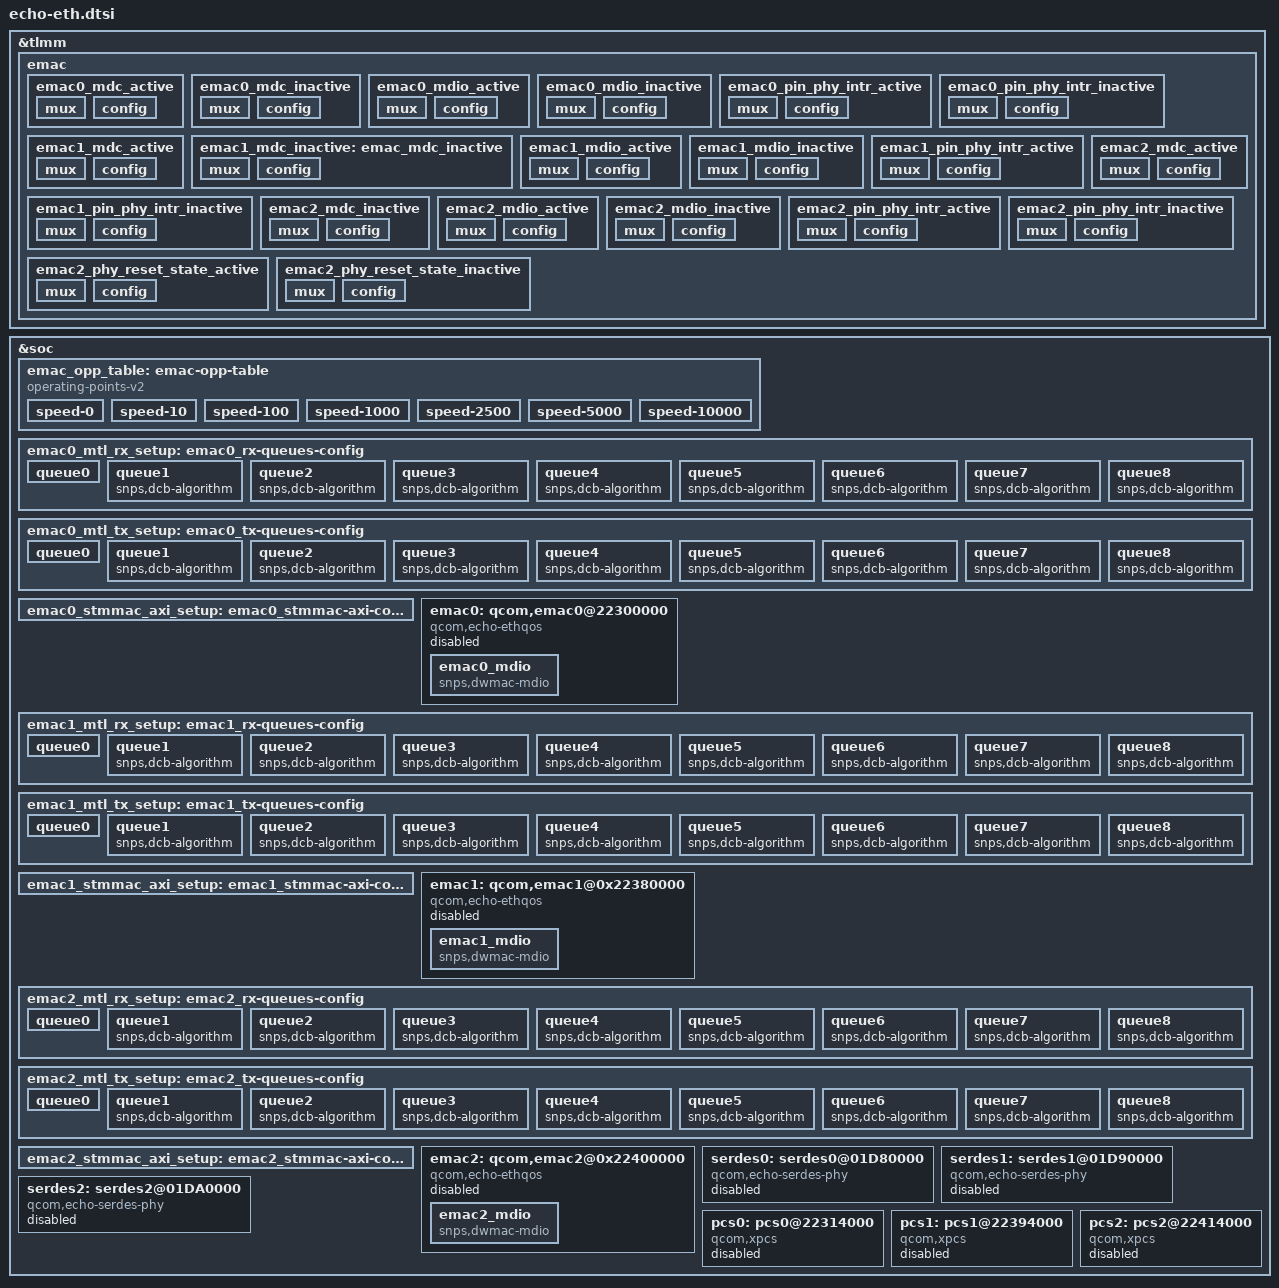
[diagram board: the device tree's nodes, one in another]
// SPDX-License-Identifier: BSD-3-Clause
/*
 * Copyright (c) Qualcomm Technologies, Inc. and/or its subsidiaries.
 */

#include <dt-bindings/clock/qcom,rpmh.h>
#include <dt-bindings/clock/qcom,echo-gcc.h>
#include <dt-bindings/clock/qcom,echo-tcsrcc.h>
#include <dt-bindings/interconnect/qcom,icc.h>
#include <dt-bindings/interconnect/qcom,echo.h>
#include <dt-bindings/interrupt-controller/arm-gic.h>
#include <dt-bindings/power/qcom,rpmhpd.h>
#include <dt-bindings/power/qcom-rpmpd.h>
#include <dt-bindings/soc/qcom,rpmh-rsc.h>
#include <dt-bindings/gpio/gpio.h>

&tlmm {
	emac {
		emac0_mdc_active: emac0_mdc_active {
			mux {
				pins = "gpio94";
				function = "eth0_mdc";
			};

			config {
				pins = "gpio94";
				bias-pull-up;
				drive-strength = <16>;
			};
		};

		emac0_mdc_inactive: emac0_mdc_inactive {
			mux {
				pins = "gpio94";
				function = "eth0_mdc";
			};

			config {
				pins = "gpio94";
				bias-pull-down;
				drive-strength = <2>;
			};
		};

		emac0_mdio_active: emac0_mdio_active {
			mux {
				pins = "gpio95";
				function = "eth0_mdio";
			};

			config {
				pins = "gpio95";
				bias-pull-up;
				drive-strength = <16>;
			};
		};

		emac0_mdio_inactive: emac0_mdio_inactive {
			mux {
				pins = "gpio95";
				function = "eth0_mdio";
			};

			config {
				pins = "gpio95";
				bias-pull-down;
				drive-strength = <2>;
			};
		};

		emac0_pin_phy_intr_active: emac0_pin_phy_intr_active {
			mux {
				pins = "gpio97";
				function = "sgmii_phy_intr0_n";
		};

			config {
				pins = "gpio97";
				drive-strength = <8>; /* 8 mA */
				bias-pull-up; /* NO PULL*/
			};
		};

		emac0_pin_phy_intr_inactive: emac0_pin_phy_intr_inactive {
			mux {
				pins = "gpio97";
				function = "sgmii_phy_intr0_n";
		};

			config {
				pins = "gpio97";
				drive-strength = <2>; /* 8 mA */
				bias-pull-down; /* NO PULL*/
			};
		};

		emac1_mdc_active: emac1_mdc_active {
			mux {
				pins = "gpio106";
				function = "eth1_mdc";
			};

			config {
				pins = "gpio106";
				bias-pull-up;
				drive-strength = <16>;
			};
		};

		emac1_mdc_inactive: emac_mdc_inactive {
			mux {
				pins = "gpio106";
				function = "eth1_mdc";
			};

			config {
				pins = "gpio106";
				bias-pull-down;
				drive-strength = <2>;
			};
		};

		emac1_mdio_active: emac1_mdio_active {
			mux {
				pins = "gpio107";
				function = "eth1_mdio";
			};

			config {
				pins = "gpio107";
				bias-pull-up;
				drive-strength = <16>;
			};
		};

		emac1_mdio_inactive: emac1_mdio_inactive {
			mux {
				pins = "gpio107";
				function = "eth1_mdio";
			};

			config {
				pins = "gpio107";
				bias-pull-down;
				drive-strength = <2>;
			};
		};

		emac1_pin_phy_intr_active: emac1_pin_phy_intr_active {
			mux {
				pins = "gpio109";
				function = "sgmii_phy_intr1_n";
		};

			config {
				pins = "gpio109";
				drive-strength = <8>; /* 8 mA */
				bias-pull-up; /* NO PULL*/
			};
		};

		emac1_pin_phy_intr_inactive: emac1_pin_phy_intr_inactive {
			mux {
				pins = "gpio109";
				function = "sgmii_phy_intr1_n";
		};

			config {
				pins = "gpio109";
				drive-strength = <2>; /* 8 mA */
				bias-pull-down; /* NO PULL*/
			};
		};

		emac2_mdc_active: emac2_mdc_active {
			mux {
				pins = "gpio86";
				function = "eth2_mdc";
			};

			config {
				pins = "gpio86";
				bias-pull-up;
				drive-strength = <16>;
			};
		};

		emac2_mdc_inactive: emac2_mdc_inactive {
			mux {
				pins = "gpio86";
				function = "eth2_mdc";
			};

			config {
				pins = "gpio86";
				bias-pull-down;
				drive-strength = <2>;
			};
		};

		emac2_mdio_active: emac2_mdio_active {
			mux {
				pins = "gpio87";
				function = "eth2_mdio";
			};

			config {
				pins = "gpio87";
				bias-pull-up;
				drive-strength = <16>;
			};
		};

		emac2_mdio_inactive: emac2_mdio_inactive {
			mux {
				pins = "gpio87";
				function = "eth2_mdio";
			};

			config {
				pins = "gpio87";
				bias-pull-down;
				drive-strength = <2>;
			};
		};

		emac2_pin_phy_intr_active: emac2_pin_phy_intr_active {
			mux {
				pins = "gpio89";
				function = "sgmii_phy_intr2_n";
		};

			config {
				pins = "gpio89";
				drive-strength = <8>; /* 8 mA */
				bias-pull-up; /* NO PULL*/
			};
		};

		emac2_pin_phy_intr_inactive: emac2_pin_phy_intr_inactive {
			mux {
				pins = "gpio89";
				function = "sgmii_phy_intr2_n";
		};

			config {
				pins = "gpio89";
				drive-strength = <2>; /* 8 mA */
				bias-pull-down; /* NO PULL*/
			};
		};

		emac2_phy_reset_state_active: emac2_phy_reset_state_active {
			mux {
				pins = "gpio88";
				function = "gpio";
			};

			config {
				pins = "gpio88";
				bias-pull-up;
				drive-strength = <16>;
			};
		};

		emac2_phy_reset_state_inactive: emac2_phy_reset_state_inactive {
			mux {
				pins = "gpio88";
				function = "gpio";
			};

			config {
				pins = "gpio88";
				bias-pull-down;
				drive-strength = <2>;
				input-enable;
			};
		};
	};
};

&soc {
	emac_opp_table: emac-opp-table {
		compatible = "operating-points-v2";

		speed-0 {
			opp-level = <0>;
			opp-avg-kBps = <0 0>;
			opp-peak-kBps = <0 0>;
		};

		speed-10 {
			opp-level = <10>;
			opp-avg-kBps = <2500 0>;
			opp-peak-kBps = <2500 2500>;
		};

		speed-100 {
			opp-level = <100>;
			opp-avg-kBps = <25000 0>;
			opp-peak-kBps = <25000 25000>;
		};

		speed-1000 {
			opp-level = <1000>;
			opp-avg-kBps = <250000 0>;
			opp-peak-kBps = <250000 250000>;
		};

		speed-2500 {
			opp-level = <2500>;
			opp-avg-kBps = <625000 0>;
			opp-peak-kBps = <625000 625000>;
		};

		speed-5000 {
			opp-level = <5000>;
			opp-avg-kBps = <1250000 0>;
			opp-peak-kBps = <1250000 1250000>;
		};

		speed-10000 {
			opp-level = <10000>;
			opp-avg-kBps = <2500000 0>;
			opp-peak-kBps = <2500000 2500000>;
		};
	};

	emac0_mtl_rx_setup: emac0_rx-queues-config {
		snps,rx-queues-to-use = <9>;
		snps,rss-queues-to-use = <1>;
		snps,rx-sched-sp;
		snps,mka_mcbcq_filtering;

		queue0 {
			snps,dcb-algorithm;
			snps,queue_depth = <16384>;
		};

		queue1 {
			snps,dcb-algorithm;
		};

		queue2 {
			snps,dcb-algorithm;
		};

		queue3 {
			snps,dcb-algorithm;
		};

		queue4 {
			snps,dcb-algorithm;
		};

		queue5 {
			snps,dcb-algorithm;
		};

		queue6 {
			snps,dcb-algorithm;
		};

		queue7 {
			snps,dcb-algorithm;
		};

		queue8 {
			snps,dcb-algorithm;
		};
	};

	emac0_mtl_tx_setup: emac0_tx-queues-config {
		snps,tx-queues-to-use = <9>;
		snps,tx-sched-sp;
		queue0 {
			snps,dcb-algorithm;
			snps,queue_depth = <16384>;
		};

		queue1 {
			snps,dcb-algorithm;
		};

		queue2 {
			snps,dcb-algorithm;
		};

		queue3 {
			snps,dcb-algorithm;
		};

		queue4 {
			snps,dcb-algorithm;
		};

		queue5 {
			snps,dcb-algorithm;
		};

		queue6 {
			snps,dcb-algorithm;
		};

		queue7 {
			snps,dcb-algorithm;
		};

		queue8 {
			snps,dcb-algorithm;
		};
	};

	emac0_stmmac_axi_setup: emac0_stmmac-axi-config {
		snps,wr_osr_lmt = <15>;
		snps,rd_osr_lmt = <15>;
		snps,axi_kbbe;
		/* If FB is disabled, the AXI master chooses
		 * a burst length of any value less than the
		 * maximum enabled burst length
		 * (all lesser burst length enables are redundant).
		 */
		snps,blen = <0 0 0 0 0 0 0>;
		snps,tdps = <0x5>;
		snps,rdps = <0x5>;
	};

	emac0: qcom,emac0@22300000 {
		compatible = "qcom,echo-ethqos", "snps,dwxgmac";
		qcom,arm-smmu;
		dma-coherent;
		iommus = <&apps_smmu 0x1041 0x0>,
			 <&apps_smmu 0x1042 0x1>,
			 <&apps_smmu 0x1044 0x3>,
			 <&apps_smmu 0x1048 0x1>,
			 <&apps_smmu 0x104F 0x0>;
		reg = <0x0 0x22300000 0x0 0x12600>,
			<0x0 0x2237F000 0x0 0x1000>;
		reg-names = "stmmaceth", "rgmii";
		clocks =<&gcc GCC_EEE_EMAC0_CLK>,
			<&gcc GCC_EMAC0_PTP_CLK>,
			<&gcc GCC_EMAC0_RGMII_CLK>,
			<&gcc GCC_EMAC0_AXI_CLK>,
			<&gcc GCC_EMAC0_SLV_AHB_CLK>;
		clock-names = "eee", "ptp_ref", "rgmii",
		"stmmaceth", "pclk";
		power-domains = <&gcc GCC_EMAC0_GDSC>;
		interrupts = <GIC_SPI 360 IRQ_TYPE_LEVEL_HIGH>,
			     <GIC_SPI 361 IRQ_TYPE_EDGE_RISING>,
			     <GIC_SPI 362 IRQ_TYPE_EDGE_RISING>,
			     <GIC_SPI 363 IRQ_TYPE_EDGE_RISING>,
			     <GIC_SPI 364 IRQ_TYPE_EDGE_RISING>,
			     <GIC_SPI 365 IRQ_TYPE_EDGE_RISING>,
			     <GIC_SPI 585 IRQ_TYPE_EDGE_RISING>,
			     <GIC_SPI 584 IRQ_TYPE_EDGE_RISING>,
			     <GIC_SPI 583 IRQ_TYPE_EDGE_RISING>,
			     <GIC_SPI 582 IRQ_TYPE_EDGE_RISING>,
			     <GIC_SPI 371 IRQ_TYPE_EDGE_RISING>,
			     <GIC_SPI 372 IRQ_TYPE_EDGE_RISING>,
			     <GIC_SPI 373 IRQ_TYPE_EDGE_RISING>,
			     <GIC_SPI 374 IRQ_TYPE_EDGE_RISING>,
			     <GIC_SPI 375 IRQ_TYPE_EDGE_RISING>,
			     <GIC_SPI 376 IRQ_TYPE_EDGE_RISING>,
			     <GIC_SPI 561 IRQ_TYPE_EDGE_RISING>,
			     <GIC_SPI 560 IRQ_TYPE_EDGE_RISING>,
			     <GIC_SPI 559 IRQ_TYPE_EDGE_RISING>;
		interrupt-names = "macirq",
				  "dma_rx0",
				  "dma_rx1",
				  "dma_rx2",
				  "dma_rx3",
				  "dma_rx4",
				  "dma_rx5",
				  "dma_rx6",
				  "dma_rx7",
				  "dma_rx8",
				  "dma_tx0",
				  "dma_tx1",
				  "dma_tx2",
				  "dma_tx3",
				  "dma_tx4",
				  "dma_tx5",
				  "dma_tx6",
				  "dma_tx7",
				  "dma_tx8";
		snps,axi-config = <&emac0_stmmac_axi_setup>;
		pinctrl-names = "default","init";
		pinctrl-0 = <&emac0_mdc_active
			     &emac0_mdio_active
			     &emac0_pin_phy_intr_active>;
		pinctrl-1 = <&emac0_mdc_inactive
			     &emac0_mdio_inactive
			     &emac0_pin_phy_intr_inactive>;

		snps,tso;
		snps,pbl = <32>;
		tx-fifo-depth = <98304>;
		rx-fifo-depth = <98304>;
		snps,mtl-rx-config = <&emac0_mtl_rx_setup>;
		snps,mtl-tx-config = <&emac0_mtl_tx_setup>;

		interconnect-names = "emac-ddr", "emac-config";
		interconnects = <&system_noc MASTER_EMAC_0 0 &mc_virt SLAVE_EBI1 0>,
				<&gem_noc MASTER_APPSS_PROC 0 &system_noc SLAVE_ETH0_CFG 0>;
		operating-points-v2 = <&emac_opp_table>;

		status = "disabled";
		qcom-xpcs-handle = <&pcs0>;
		phys = <&serdes0>;
		phy-names = "serdes";
		emac0_mdio: emac0_mdio {
			compatible = "snps,dwmac-mdio";
			#address-cells = <1>;
			#size-cells = <0>;
		};
	};

	emac1_mtl_rx_setup: emac1_rx-queues-config {
		snps,rx-queues-to-use = <9>;
		snps,rss-queues-to-use = <1>;
		snps,rx-sched-sp;
		snps,mka_mcbcq_filtering;

		queue0 {
			snps,dcb-algorithm;
			snps,queue_depth = <16384>;
		};

		queue1 {
			snps,dcb-algorithm;
		};

		queue2 {
			snps,dcb-algorithm;
		};

		queue3 {
			snps,dcb-algorithm;
		};

		queue4 {
			snps,dcb-algorithm;
		};

		queue5 {
			snps,dcb-algorithm;
		};

		queue6 {
			snps,dcb-algorithm;
		};

		queue7 {
			snps,dcb-algorithm;
		};

		queue8 {
			snps,dcb-algorithm;
		};
	};

	emac1_mtl_tx_setup: emac1_tx-queues-config {
		snps,tx-queues-to-use = <9>;
		snps,tx-sched-sp;
		queue0 {
			snps,dcb-algorithm;
			snps,queue_depth = <16384>;
		};

		queue1 {
			snps,dcb-algorithm;
		};

		queue2 {
			snps,dcb-algorithm;
		};

		queue3 {
			snps,dcb-algorithm;
		};

		queue4 {
			snps,dcb-algorithm;
		};

		queue5 {
			snps,dcb-algorithm;
		};

		queue6 {
			snps,dcb-algorithm;
		};

		queue7 {
			snps,dcb-algorithm;
		};

		queue8 {
			snps,dcb-algorithm;
		};
	};


	emac1_stmmac_axi_setup: emac1_stmmac-axi-config {
		snps,wr_osr_lmt = <15>;
		snps,rd_osr_lmt = <15>;
		snps,axi_kbbe;
		/* If FB is disabled, the AXI master chooses
		 * a burst length of any value less than the
		 * maximum enabled burst length
		 * (all lesser burst length enables are redundant).
		 */
		snps,blen = <0 0 0 0 0 0 0>;
		snps,tdps = <0x5>;
		snps,rdps = <0x5>;
	};

	emac1: qcom,emac1@0x22380000 {
		compatible = "qcom,echo-ethqos", "snps,dwxgmac";
		qcom,arm-smmu;
		dma-coherent;
		iommus = <&apps_smmu 0x1061 0x0>,
			 <&apps_smmu 0x1062 0x1>,
			 <&apps_smmu 0x1064 0x3>,
			 <&apps_smmu 0x1068 0x1>,
			 <&apps_smmu 0x106F 0x0>;
		reg = <0x0 0x22380000 0x0 0x12600>,
			<0x0 0x223FF000 0x0 0x1000>;
		reg-names = "stmmaceth", "rgmii";
		clocks =<&gcc GCC_EEE_EMAC1_CLK>,
			<&gcc GCC_EMAC1_AXI_CLK>,
			<&gcc GCC_EMAC1_PTP_CLK>,
			<&gcc GCC_EMAC1_RGMII_CLK>,
			<&gcc GCC_EMAC1_SLV_AHB_CLK>;
		clock-names = "eee", "stmmaceth", "ptp_ref", "rgmii",
		"pclk";
		power-domains = <&gcc GCC_EMAC1_GDSC>;
		interrupts = <GIC_SPI 445 IRQ_TYPE_LEVEL_HIGH>,
			     <GIC_SPI 366 IRQ_TYPE_EDGE_RISING>,
			     <GIC_SPI 367 IRQ_TYPE_EDGE_RISING>,
			     <GIC_SPI 588 IRQ_TYPE_EDGE_RISING>,
			     <GIC_SPI 587 IRQ_TYPE_EDGE_RISING>,
			     <GIC_SPI 586 IRQ_TYPE_EDGE_RISING>,
			     <GIC_SPI 581 IRQ_TYPE_EDGE_RISING>,
			     <GIC_SPI 580 IRQ_TYPE_EDGE_RISING>,
			     <GIC_SPI 579 IRQ_TYPE_EDGE_RISING>,
			     <GIC_SPI 578 IRQ_TYPE_EDGE_RISING>,
			     <GIC_SPI 377 IRQ_TYPE_EDGE_RISING>,
			     <GIC_SPI 378 IRQ_TYPE_EDGE_RISING>,
			     <GIC_SPI 565 IRQ_TYPE_EDGE_RISING>,
			     <GIC_SPI 564 IRQ_TYPE_EDGE_RISING>,
			     <GIC_SPI 563 IRQ_TYPE_EDGE_RISING>,
			     <GIC_SPI 562 IRQ_TYPE_EDGE_RISING>,
			     <GIC_SPI 577 IRQ_TYPE_EDGE_RISING>,
			     <GIC_SPI 576 IRQ_TYPE_EDGE_RISING>,
			     <GIC_SPI 575 IRQ_TYPE_EDGE_RISING>;
		interrupt-names = "macirq",
				  "dma_rx0",
				  "dma_rx1",
				  "dma_rx2",
				  "dma_rx3",
				  "dma_rx4",
				  "dma_rx5",
				  "dma_rx6",
				  "dma_rx7",
				  "dma_rx8",
				  "dma_tx0",
				  "dma_tx1",
				  "dma_tx2",
				  "dma_tx3",
				  "dma_tx4",
				  "dma_tx5",
				  "dma_tx6",
				  "dma_tx7",
				  "dma_tx8";
		snps,axi-config = <&emac1_stmmac_axi_setup>;
		pinctrl-names = "default","init";
		pinctrl-0 = <&emac1_mdc_active
			     &emac1_mdio_active
			     &emac1_pin_phy_intr_active>;
		pinctrl-1 = <&emac1_mdc_inactive
			     &emac1_mdio_inactive
			     &emac1_pin_phy_intr_inactive>;

		snps,tso;
		snps,pbl = <32>;
		tx-fifo-depth = <98304>;
		rx-fifo-depth = <98304>;
		snps,mtl-rx-config = <&emac1_mtl_rx_setup>;
		snps,mtl-tx-config = <&emac1_mtl_tx_setup>;
		phys = <&serdes1>;
		phy-names = "serdes";

		interconnect-names = "emac-ddr", "emac-config";
		interconnects = <&system_noc MASTER_EMAC_1 0 &mc_virt SLAVE_EBI1 0>,
				<&gem_noc MASTER_APPSS_PROC 0 &system_noc SLAVE_ETH1_CFG 0>;
		operating-points-v2 = <&emac_opp_table>;

		status = "disabled";
		qcom-xpcs-handle = <&pcs1>;
		emac1_mdio: emac1_mdio {
			compatible = "snps,dwmac-mdio";
			#address-cells = <1>;
			#size-cells = <0>;
		};
	};

	emac2_mtl_rx_setup: emac2_rx-queues-config {
		snps,rx-queues-to-use = <9>;
		snps,rss-queues-to-use = <1>;
		snps,rx-sched-sp;
		snps,mka_mcbcq_filtering;

		queue0 {
			snps,dcb-algorithm;
			qcom,ipa_offload;
			snps,queue_depth = <16384>;
		};

		queue1 {
			snps,dcb-algorithm;
		};

		queue2 {
			snps,dcb-algorithm;
		};

		queue3 {
			snps,dcb-algorithm;
		};

		queue4 {
			snps,dcb-algorithm;
		};

		queue5 {
			snps,dcb-algorithm;
		};

		queue6 {
			snps,dcb-algorithm;
		};

		queue7 {
			snps,dcb-algorithm;
		};

		queue8 {
			snps,dcb-algorithm;
		};
	};

	emac2_mtl_tx_setup: emac2_tx-queues-config {
		snps,tx-queues-to-use = <9>;
		snps,tx-sched-sp;
		queue0 {
			snps,dcb-algorithm;
			qcom,ipa_offload;
			snps,queue_depth = <16384>;
		};

		queue1 {
			snps,dcb-algorithm;
		};

		queue2 {
			snps,dcb-algorithm;
		};

		queue3 {
			snps,dcb-algorithm;
		};

		queue4 {
			snps,dcb-algorithm;
		};

		queue5 {
			snps,dcb-algorithm;
		};

		queue6 {
			snps,dcb-algorithm;
		};

		queue7 {
			snps,dcb-algorithm;
		};

		queue8 {
			snps,dcb-algorithm;
		};
	};

	emac2_stmmac_axi_setup: emac2_stmmac-axi-config {
		snps,wr_osr_lmt = <15>;
		snps,rd_osr_lmt = <15>;
		snps,axi_kbbe;
		/* If FB is disabled, the AXI master chooses
		 * a burst length of any value less than the
		 * maximum enabled burst length
		 * (all lesser burst length enables are redundant).
		 */
		snps,blen = <0 0 0 0 0 0 0>;
		snps,tdps = <0x5>;
		snps,rdps = <0x5>;
	};

	emac2: qcom,emac2@0x22400000 {
		compatible = "qcom,echo-ethqos", "snps,dwxgmac";
		qcom,arm-smmu;
		dma-coherent;
		iommus = <&apps_smmu 0x1081 0x0>,
			 <&apps_smmu 0x1082 0x1>,
			 <&apps_smmu 0x1084 0x3>,
			 <&apps_smmu 0x1088 0x1>,
			 <&apps_smmu 0x108F 0x0>;
		reg = <0x0 0x22400000 0x0 0x12600>,
			<0x0 0x2247F000 0x0 0x1000>;
		reg-names = "stmmaceth", "rgmii";
		clocks =<&gcc GCC_EEE_EMAC2_CLK>,
			<&gcc GCC_EMAC2_AXI_CLK>,
			<&gcc GCC_EMAC2_PTP_CLK>,
			<&gcc GCC_EMAC2_RGMII_CLK>,
			<&gcc GCC_EMAC2_SLV_AHB_CLK>;
		clock-names = "eee", "stmmaceth", "ptp_ref", "rgmii",
		"pclk";
		power-domains = <&gcc GCC_EMAC2_GDSC>;
		interrupts = <GIC_SPI 599 IRQ_TYPE_LEVEL_HIGH>,
			     <GIC_SPI 597 IRQ_TYPE_EDGE_RISING>,
			     <GIC_SPI 596 IRQ_TYPE_EDGE_RISING>,
			     <GIC_SPI 595 IRQ_TYPE_EDGE_RISING>,
			     <GIC_SPI 594 IRQ_TYPE_EDGE_RISING>,
			     <GIC_SPI 593 IRQ_TYPE_EDGE_RISING>,
			     <GIC_SPI 592 IRQ_TYPE_EDGE_RISING>,
			     <GIC_SPI 591 IRQ_TYPE_EDGE_RISING>,
			     <GIC_SPI 590 IRQ_TYPE_EDGE_RISING>,
			     <GIC_SPI 589 IRQ_TYPE_EDGE_RISING>,
			     <GIC_SPI 574 IRQ_TYPE_EDGE_RISING>,
			     <GIC_SPI 573 IRQ_TYPE_EDGE_RISING>,
			     <GIC_SPI 572 IRQ_TYPE_EDGE_RISING>,
			     <GIC_SPI 571 IRQ_TYPE_EDGE_RISING>,
			     <GIC_SPI 570 IRQ_TYPE_EDGE_RISING>,
			     <GIC_SPI 569 IRQ_TYPE_EDGE_RISING>,
			     <GIC_SPI 568 IRQ_TYPE_EDGE_RISING>,
			     <GIC_SPI 567 IRQ_TYPE_EDGE_RISING>,
			     <GIC_SPI 566 IRQ_TYPE_EDGE_RISING>;
		interrupt-names = "macirq",
				  "dma_rx0",
				  "dma_rx1",
				  "dma_rx2",
				  "dma_rx3",
				  "dma_rx4",
				  "dma_rx5",
				  "dma_rx6",
				  "dma_rx7",
				  "dma_rx8",
				  "dma_tx0",
				  "dma_tx1",
				  "dma_tx2",
				  "dma_tx3",
				  "dma_tx4",
				  "dma_tx5",
				  "dma_tx6",
				  "dma_tx7",
				  "dma_tx8";
		snps,axi-config = <&emac2_stmmac_axi_setup>;
		pinctrl-names = "default","init";
		pinctrl-0 = <&emac2_mdc_active
			     &emac2_mdio_active
			     &emac2_pin_phy_intr_active
			     &emac2_phy_reset_state_active>;
		pinctrl-1 = <&emac2_mdc_inactive
			     &emac2_mdio_inactive
			     &emac2_pin_phy_intr_inactive
			     &emac2_phy_reset_state_inactive>;

		snps,tso;
		snps,pbl = <32>;
		tx-fifo-depth = <98304>;
		rx-fifo-depth = <98304>;
		snps,mtl-rx-config = <&emac2_mtl_rx_setup>;
		snps,mtl-tx-config = <&emac2_mtl_tx_setup>;

		interconnect-names = "emac-ddr", "emac-config";
		interconnects = <&system_noc MASTER_EMAC_2 0 &mc_virt SLAVE_EBI1 0>,
				<&gem_noc MASTER_APPSS_PROC 0 &system_noc SLAVE_ETH2_CFG 0>;
		operating-points-v2 = <&emac_opp_table>;

		status = "disabled";
		qcom-xpcs-handle = <&pcs2>;
		phys = <&serdes2>;
		phy-names = "serdes";

		emac2_mdio: emac2_mdio {
			compatible = "snps,dwmac-mdio";
			#address-cells = <1>;
			#size-cells = <0>;
		};
	};

	serdes0: serdes0@01D80000 {
		status = "disabled";
		compatible = "qcom,echo-serdes-phy";
		reg = <0x0 0x01D80000 0x0 0x1010>;
		reg-names = "serdes";
		clocks = <&tcsrcc TCSR_ETH_0_CLKREF_EN>,
			 <&gcc GCC_EMAC0_PHY_AUX_CLK>,
			 <&gcc GCC_EMAC0_SLV_AHB_CLK>,
			 <&gcc GCC_EMAC0_CC_SGMIIPHY_RX_CLK>,
			 <&gcc GCC_EMAC0_CC_SGMIIPHY_TX_CLK>;
		clock-names = "sgmi_ref", "phyaux", "pclk",
		"sgmii_rx", "sgmii_tx";
		power-domains = <&gcc GCC_EMAC0_GDSC>;
		vreg_1p2-supply = <&vreg_l1b_1p2>;
		vreg_0p9-supply = <&vreg_l4b_0p8>;
		#phy-cells = <0>;
	};

	serdes1: serdes1@01D90000 {
		status = "disabled";
		compatible = "qcom,echo-serdes-phy";
		reg = <0x0 0x01D90000 0x0 0x1010>;
		reg-names = "serdes";
		clocks = <&tcsrcc TCSR_ETH_1_CLKREF_EN>,
			 <&gcc GCC_EMAC1_PHY_AUX_CLK>,
			 <&gcc GCC_EMAC1_SLV_AHB_CLK>,
			 <&gcc GCC_EMAC1_CC_SGMIIPHY_RX_CLK>,
			 <&gcc GCC_EMAC1_CC_SGMIIPHY_TX_CLK>;
		clock-names = "sgmi_ref", "phyaux", "pclk",
		"sgmii_rx", "sgmii_tx";
		power-domains = <&gcc GCC_EMAC1_GDSC>;
		vreg_1p2-supply = <&vreg_l1b_1p2>;
		vreg_0p9-supply = <&vreg_l4b_0p8>;
		#phy-cells = <0>;
	};

	serdes2: serdes2@01DA0000 {
		status = "disabled";
		compatible = "qcom,echo-serdes-phy";
		reg = <0x0 0x01DA0000 0x0 0x1010>;
		reg-names = "serdes";
		clocks = <&tcsrcc TCSR_ETH_2_CLKREF_EN>,
			 <&gcc GCC_EMAC2_PHY_AUX_CLK>,
			 <&gcc GCC_EMAC2_SLV_AHB_CLK>,
			 <&gcc GCC_EMAC2_CC_SGMIIPHY_RX_CLK>,
			 <&gcc GCC_EMAC2_CC_SGMIIPHY_TX_CLK>;
		clock-names = "sgmi_ref", "phyaux", "pclk",
		"sgmii_rx", "sgmii_tx";
		power-domains = <&gcc GCC_EMAC2_GDSC>;
		vreg_1p2-supply = <&vreg_l1b_1p2>;
		vreg_0p9-supply = <&vreg_l4b_0p8>;
		#phy-cells = <0>;
	};

	pcs0: pcs0@22314000 {
		status = "disabled";
		compatible = "qcom,xpcs";
		reg = <0x0 0x22314000 0x0 0x5100>;
		reg-names = "qxpcs";
		clocks = <&gcc GCC_EMAC0_RPCS_RX_CLK>,
			<&gcc GCC_EMAC0_RPCS_TX_CLK>,
			<&gcc GCC_EMAC0_XGXS_RX_CLK>,
			<&gcc GCC_EMAC0_XGXS_TX_CLK>,
			<&gcc GCC_EMAC0_SLV_AHB_CLK>;
		clock-names = "rpcs_rx", "rpcs_tx", "xgxs_rx", "xgxs_tx", "pclk";
		power-domains = <&gcc GCC_EMAC0_GDSC>;
		interrupts = <GIC_SPI 417 IRQ_TYPE_LEVEL_HIGH>;
		interrupt-names = "pcs_intr";
	};

	pcs1: pcs1@22394000 {
		status = "disabled";
		compatible = "qcom,xpcs";
		reg = <0x0 0x22394000 0x0 0x5100>;
		reg-names = "qxpcs";
		clocks = <&gcc GCC_EMAC1_RPCS_RX_CLK>,
			<&gcc GCC_EMAC1_RPCS_TX_CLK>,
			<&gcc GCC_EMAC1_XGXS_RX_CLK>,
			<&gcc GCC_EMAC1_XGXS_TX_CLK>,
			<&gcc GCC_EMAC1_SLV_AHB_CLK>;
		clock-names = "rpcs_rx", "rpcs_tx", "xgxs_rx", "xgxs_tx", "pclk";
		power-domains = <&gcc GCC_EMAC1_GDSC>;
		interrupts = <GIC_SPI 418 IRQ_TYPE_LEVEL_HIGH>;
		interrupt-names = "pcs_intr";
	};

	pcs2: pcs2@22414000 {
		status = "disabled";
		compatible = "qcom,xpcs";
		reg = <0x0 0x22414000 0x0 0x5100>;
		reg-names = "qxpcs";
		clocks = <&gcc GCC_EMAC2_RPCS_RX_CLK>,
			<&gcc GCC_EMAC2_RPCS_TX_CLK>,
			<&gcc GCC_EMAC2_XGXS_RX_CLK>,
			<&gcc GCC_EMAC2_XGXS_TX_CLK>,
			<&gcc GCC_EMAC2_SLV_AHB_CLK>;
		clock-names = "rpcs_rx", "rpcs_tx", "xgxs_rx", "xgxs_tx", "pclk";
		power-domains = <&gcc GCC_EMAC2_GDSC>;
		interrupts = <GIC_SPI 598 IRQ_TYPE_LEVEL_HIGH>;
		interrupt-names = "pcs_intr";
	};
};
